# R7FA4L1BD register map
Vendor: Renesas Electronics Corporation; Series: RA4; File version: 0.90.02
CPU: CM33 r0p4, little endian, MPU, FPU, VTOR, 4 interrupt priority bits, 96 interrupts
Registers are 32-bit, read-write, reset 0x0 unless marked. A register's access mark holds for its fields unless they carry their own. Offsets are from the block's base; [hi:lo] are bit positions; {n}, {i} and the like mark numbered series; <NAME> marks a mode.

## SYSC — System Control
Base 0x4001E000
0x0C SBYCR 16-bit — Standby Control Register
  [15] SSBY — Software Standby Mode Select
    0=Sleep mode; 1=Software Standby mode
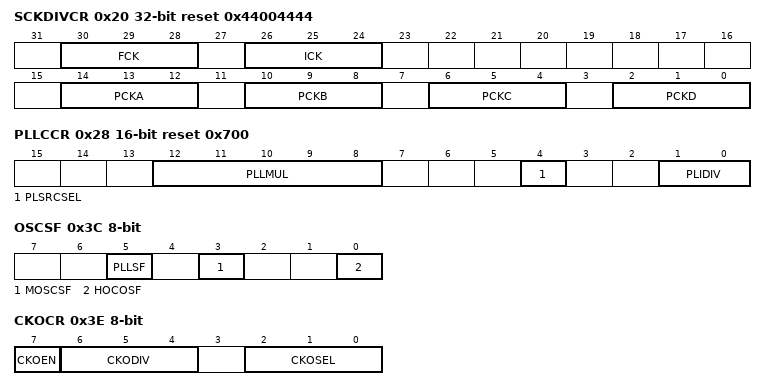
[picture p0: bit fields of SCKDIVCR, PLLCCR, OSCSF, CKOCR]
0x20 SCKDIVCR reset 0x44004444 — System Clock Division Control Register
  [all] fields
    0=x 1/1; 1=x 1/2; 2=x 1/4; 3=x 1/8; 4=x 1/16; 5=x 1/32; 6=x 1/64; other=Others (Setting prohibited.)
  [30:28] FCK — FlashIF Clock (FCLK) Select
  [26:24] ICK — System Clock (ICLK) Select
  [14:12] PCKA — Peripheral Module Clock A (PCLKA) Select
  [10:8] PCKB — Peripheral Module Clock B (PCLKB) Select
  [6:4] PCKC — Peripheral Module Clock C (PCLKC) Select
  [2:0] PCKD — Peripheral Module Clock D (PCLKD) Select
0x26 SCKSCR 8-bit reset 0x1 — System Clock Source Control Register
  [2:0] CKSEL — Clock Source Select
    0=HOCO; 1=MOCO; 2=LOCO; 3=Main clock oscillator (MOSC); 4=Sub-clock oscillator (SOSC); 5=PLL; 6=Setting prohibited; 7=Setting prohibited
0x28 PLLCCR 16-bit reset 0x700 — PLL Clock Control Register
  [12:8] PLLMUL range 0x13..0x3B — PLL Frequency Multiplication Factor Select
  [4] PLSRCSEL — PLL Clock Source Select
    0=Main clock oscillator; 1=HOCO
  [1:0] PLIDIV — PLL Input Frequency Division Ratio Select
    0=/1; 1=/4; 2=/6; other=Others (Setting prohibited)
0x2A PLLCR 8-bit reset 0x1 — PLL Control Register
  [0] PLLSTP — PLL Stop Control
    0=PLL is operating; 1=PLL is stopped
0x31 MEMWAIT 8-bit — Memory Wait Cycle Control Register for Code Flash
  [1:0] MEMWAIT — Memory Wait Cycle Select for Code Flash
    0=No wait; 1=One wait; 2=Two waits; other=Others (Setting prohibited)
0x32 MOSCCR 8-bit reset 0x1 — Main Clock Oscillator Control Register
  [0] MOSTP — Main Clock Oscillator Stop
    0=Operate the main clock oscillator; 1=Stop the main clock oscillator
0x36 HOCOCR 8-bit (reset mask 0xFE) — High-Speed On-Chip Oscillator Control Register
  [0] HCSTP — HOCO Stop
    0=Operate the HOCO clock; 1=Stop the HOCO clock
0x38 MOCOCR 8-bit — Middle-Speed On-Chip Oscillator Control Register
  [0] MCSTP — MOCO Stop
    0=MOCO clock is operating; 1=MOCO clock is stopped
0x3C OSCSF 8-bit ro (reset mask 0xFE) — Oscillation Stabilization Flag Register
  [5] PLLSF — PLL Clock Oscillation Stabilization Flag
    0=The PLL clock is stopped, or oscillation of the PLL clock is not stable yet; 1=The PLL clock is stable, so is available for use as the system clock
  [3] MOSCSF — Main Clock Oscillation Stabilization Flag
    0=The main clock oscillator is stopped (MOSTP = 1) or is not yet stable; 1=The main clock oscillator is stable, so is available for use as the system clock
  [0] HOCOSF — HOCO Clock Oscillation Stabilization Flag
    0=The HOCO clock is stopped or is not yet stable; 1=The HOCO clock is stable, so is available for use as the system clock
0x3E CKOCR 8-bit — Clock Out Control Register
  [7] CKOEN — Clock Out Enable
    0=Disable clock out; 1=Enable clock out
  [6:4] CKODIV — Clock Output Frequency Division Ratio
    0=x 1/1; 1=x 1/2; 2=x 1/4; 3=x 1/8; 4=x 1/16; 5=x 1/32; 6=x 1/64; 7=x 1/128
  [2:0] CKOSEL — Clock Out Source Select
    0=HOCO (value after reset); 1=MOCO; 2=LOCO; 3=MOSC; 4=SOSC; other=Others (Setting prohibited)
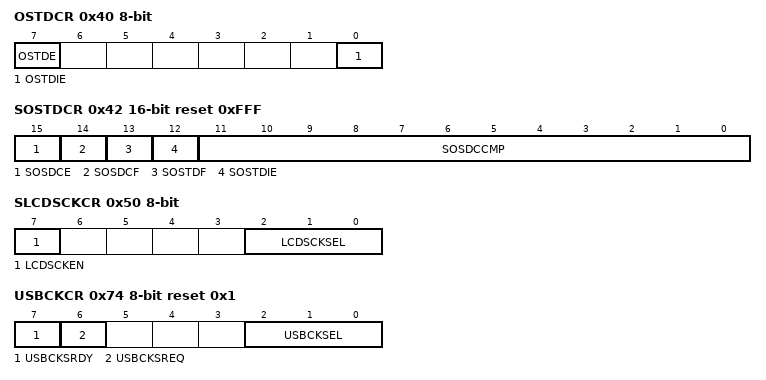
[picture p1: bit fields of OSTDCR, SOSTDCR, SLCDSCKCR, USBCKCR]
0x40 OSTDCR 8-bit — Oscillation Stop Detection Control Register
  [7] OSTDE — Oscillation Stop Detection Function Enable
    0=Disable oscillation stop detection function; 1=Enable oscillation stop detection function
  [0] OSTDIE — Oscillation Stop Detection Interrupt Enable
    0=Disable oscillation stop detection interrupt (do not notify the POEG); 1=Enable oscillation stop detection interrupt (notify the POEG)
0x41 OSTDSR 8-bit — Oscillation Stop Detection Status Register
  [0] OSTDF — Oscillation Stop Detection Flag
    0=Main clock oscillation stop not detected; 1=Main clock oscillation stop detected
0x42 SOSTDCR 16-bit reset 0xFFF — Sub-Clock Oscillation Stop Detection Control Register
  [15] SOSDCE — Control of Sub-Clock Oscillation Stop Detector Operation
    0=Stop operation of the sub-clock oscillation stop detector; 1=Start operation of the sub-clock oscillation stop detector
  [14] SOSDCF ro — Status of Sub-Clock Oscillation Stop Detector Operation
    0=Stop operation of the sub-clock oscillation stop detector; 1=Run operation of the sub-clock oscillation stop detector
  [13] SOSTDF ro — Sub-Clock Oscillation Stop Detection Flag
    0=Sub-clock oscillation stop not detected; 1=Sub-clock oscillation stop detected
  [12] SOSTDIE — Sub-Clock Oscillation Stop Detection Interrupt Enable
    0=Disable sub-clock oscillation stop detection interrupt; 1=Enable sub-clock oscillation stop detection interrupt
  [11:0] SOSDCCMP — Sub-Clock Oscillation Stop Detection Time
0x50 SLCDSCKCR 8-bit — Segment LCD Source Clock Control Register
  [7] LCDSCKEN — Segment LCD Source Clock (LCDSRCCLK) Out Enable
    0=Segment LCD source clock out is disabled; 1=Segment LCD source clock out is enabled
  [2:0] LCDSCKSEL — Segment LCD Source Clock (LCDSRCCLK) Select
    0=LOCO; 1=SOSC; 2=MOSC; 4=HOCO; other=Others (Setting prohibited)
0x61 MOCOUTCR 8-bit — MOCO User Trimming Control Register
  [7:0] MOCOUTRM — MOCO User Trimming
0x62 HOCOUTCR 8-bit — HOCO User Trimming Control Register
  [7:0] HOCOUTRM — HOCO User Trimming
0x6E CANFDCKDIVCR 8-bit — CANFD Clock Division Control Register
  [2:0] CANFDCKDIV — CANFD clock (CANFDCLK) Division Select
    0=/1 (value after reset); 1=/2; 2=/4; 3=/6; 4=/8; other=Others (Setting prohibited)
0x71 I3CCKDIVCR 8-bit — I3C Clock Division Control Register
  [2:0] I3CCKDIV — I3C Clock (I3CCLK) Division Select
    0=/1 (value after reset); 1=/2; 2=/4; 3=/6; 4=/8; 5=/3; 6=/5; other=Others (Setting prohibited)
0x74 USBCKCR 8-bit reset 0x1 — USB Clock Control Register
  [7] USBCKSRDY ro — USB Clock (USBCLK) Switching Ready state flag
    0=Impossible to Switch; 1=Possible to Switch
  [6] USBCKSREQ — USB Clock (USBCLK) Switching Request
    0=No request; 1=Request switching
  [2:0] USBCKSEL — USB Clock (USBCLK) Source Select
    5=PLL; other=Others (Setting prohibited.)
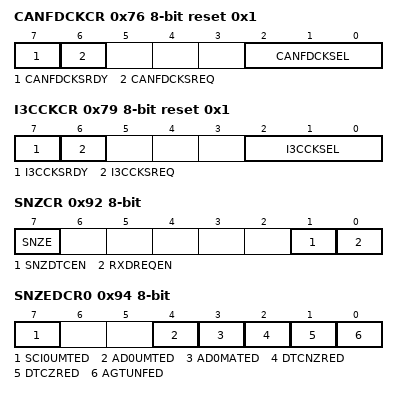
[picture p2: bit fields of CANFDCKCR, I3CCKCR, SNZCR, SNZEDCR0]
0x76 CANFDCKCR 8-bit reset 0x1 — CANFD Clock Control Register
  [7] CANFDCKSRDY ro — CANFD clock (CANFDCLK) Switching Ready State Flag
    0=Switching not possible; 1=Switching possible
  [6] CANFDCKSREQ — CANFD clock (CANFDCLK) Switching Request
    0=No request; 1=Request switching
  [2:0] CANFDCKSEL — CANFD clock (CANFDCLK) Source Select
    0=HOCO; 1=MOCO (value after reset); 2=LOCO; 3=Main clock oscillator; 4=Sub-clock oscillator; 5=PLL; other=Others (Setting prohibited)
0x79 I3CCKCR 8-bit reset 0x1 — I3C Clock Control Register
  [7] I3CCKSRDY ro — I3C clock (I3CCLK) Switching Ready State Flag
    0=Impossible to switch; 1=Possible to switch
  [6] I3CCKSREQ — I3C clock (I3CCLK) Switching Request
    0=No request; 1=Request switching
  [2:0] I3CCKSEL — I3C clock (I3CCLK) Source Select
    0=HOCO; 1=MOCO (value after reset); 2=LOCO; 3=Main clock oscillator; 4=Sub-clock oscillator; 5=PLL
0x92 SNZCR 8-bit — Snooze Control Register
  [7] SNZE — Snooze mode Enable
    0=Disable Snooze mode; 1=Enable Snooze mode
  [1] SNZDTCEN — DTC Enable in Snooze mode
    0=Disable DTC operation; 1=Enable DTC operation
  [0] RXDREQEN — RXD0 Snooze Request Enable
    0=Ignore RXD0 falling edge in Software Standby mode; 1=Detect RXD0 falling edge in Software Standby mode
0x94 SNZEDCR0 8-bit — Snooze End Control Register 0
  [all] fields
    0=Disable the snooze end request; 1=Enable the snooze end request
  [7] SCI0UMTED — SCI0 Address Mismatch Snooze End Enable
  [4] AD0UMTED — ADC12 Compare Mismatch Snooze End Enable
  [3] AD0MATED — ADC12 Compare Match Snooze End Enable
  [2] DTCNZRED — Not Last DTC Transmission Completion Snooze End Enable
  [1] DTCZRED — Last DTC Transmission Completion Snooze End Enable
  [0] AGTUNFED — AGT1 Underflow Snooze End Enable
0x95 SNZEDCR1 8-bit — Snooze End Control Register 1
  [1] CTSUNAJED — CTSU non-touch automatic judgment Snooze End Enable
    0=Disable the Snooze End request; 1=Enable the Snooze End request
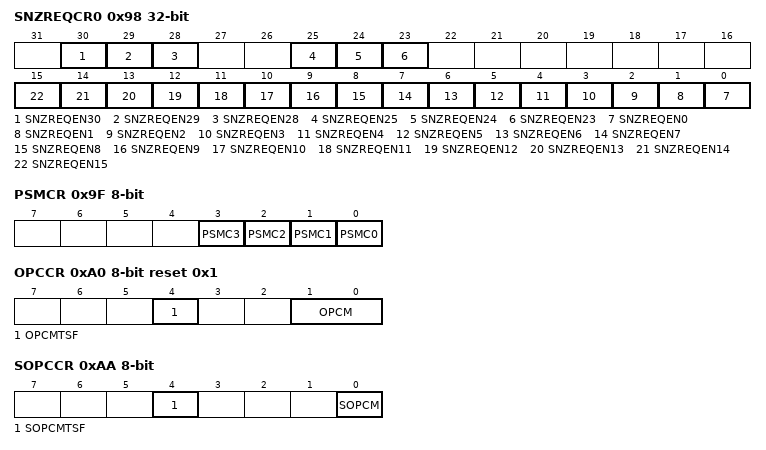
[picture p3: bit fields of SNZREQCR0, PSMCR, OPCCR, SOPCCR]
0x98 SNZREQCR0 — Snooze Request Control Register 0
  [all] fields
    0=Disable the snooze request; 1=Enable the snooze request
  [30] SNZREQEN30 — Enable AGT1 compare match B snooze request
  [29] SNZREQEN29 — Enable AGT1 compare match A snooze request
  [28] SNZREQEN28 — Enable AGT1 underflow snooze request
  [25] SNZREQEN25 — Enable RTC period snooze request
  [24] SNZREQEN24 — Enable RTC alarm snooze request
  [23] SNZREQEN23 — Enable ACMP_LP0 snooze request
  [n] SNZREQEN{n} (n=0..15) — Enable IRQ{n} pin snooze request
0x9F PSMCR 8-bit — Power Save Memory Control Register
  [3] PSMC3 — Power Save Memory Control bit 3
    0=The SRAM data of 0x2000_C000 to 0x2000_FFFF area is retained in Software Standby mode; 1=The SRAM data of 0x2000_C000 to 0x2000_FFFF area is not retained in Software Standby mode
  [2] PSMC2 — Power Save Memory Control bit 2
    0=The SRAM data of 0x2000_8000 to 0x2000_BFFF area is retained in Software Standby mode; 1=The SRAM data of 0x2000_8000 to 0x2000_BFFF area is not retained in Software Standby mode
  [1] PSMC1 — Power Save Memory Control bit 1
    0=The SRAM data of 0x2000_4000 to 0x2000_7FFF area is retained in Software Standby mode; 1=The SRAM data of 0x2000_4000 to 0x2000_7FFF area is not retained in Software Standby mode
  [0] PSMC0 — Power Save Memory Control bit 0
    0=The SRAM data of 0x2000_0000 to 0x2000_3FFF area is retained in Software Standby mode; 1=The SRAM data of 0x2000_0000 to 0x2000_3FFF area is not retained in Software Standby mode
0xA0 OPCCR 8-bit reset 0x1 — Operating Power Control Register
  [4] OPCMTSF ro — Operating Power Control Mode Transition Status Flag
    0=Transition completed; 1=During transition
  [1:0] OPCM — Operating Power Control Mode Select
    0=High-speed mode; 1=Middle-speed mode; 2=Setting prohibited; 3=Low-speed mode
0xA2 MOSCWTCR 8-bit reset 0x5 — Main Clock Oscillator Wait Control Register
  [3:0] MSTS — Main Clock Oscillator Wait Time Setting
    0=Wait time = 2 cycles (0.25 us); 1=Wait time = 1024 cycles (128 us); 2=Wait time = 2048 cycles (256 us); 3=Wait time = 4096 cycles (512 us); 4=Wait time = 8192 cycles (1024 us); 5=Wait time = 16384 cycles (2048 us); 6=Wait time = 32768 cycles (4096 us); 7=Wait time = 65536 cycles (8192 us); 8=Wait time = 131072 cycles (16384 us); 9=Wait time = 262144 cycles (32768 us); other=Others (Setting prohibited)
0xAA SOPCCR 8-bit — Sub Operating Power Control Register
  [4] SOPCMTSF ro — Operating Power Control Mode Transition Status Flag
    0=Transition completed; 1=During transition
  [0] SOPCM — Sub Operating Power Control Mode Select
    0=Other than Subosc-speed mode; 1=Subosc-speed mode
0xAC LDOCR 8-bit — LDO Control Register
  [0] CHG0 — Charge up 0
    0=LDO normal operating mode; 1=LDO high performance mode
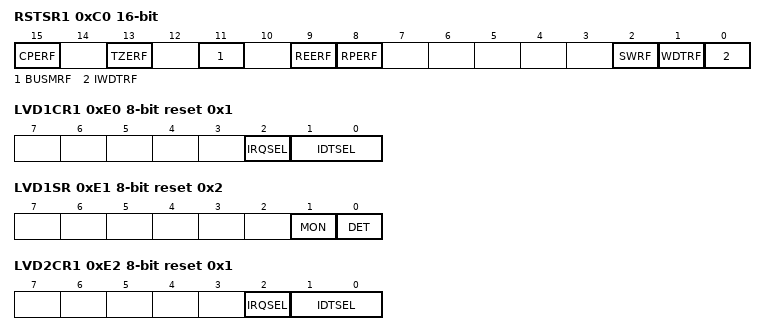
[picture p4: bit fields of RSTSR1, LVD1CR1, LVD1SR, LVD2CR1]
0xC0 RSTSR1 16-bit (reset mask 0x54F8) — Reset Status Register 1
  [15] CPERF — Cache Parity Error Reset Detect Flag
    0=Cache Parity error reset not detected; 1=Cache Parity error reset detected
  [13] TZERF — TrustZone Error Reset Detect Flag
    0=TrustZone error reset not detected; 1=TrustZone error reset detected
  [11] BUSMRF — Bus Master MPU Error Reset Detect Flag
    0=Bus master MPU error reset not detected; 1=Bus master MPU error reset detected
  [9] REERF — SRAM ECC Error Reset Detect Flag
    0=SRAM ECC error reset not detected; 1=SRAM ECC error reset detected
  [8] RPERF — SRAM Parity Error Reset Detect Flag
    0=SRAM parity error reset not detected; 1=SRAM parity error reset detected
  [2] SWRF — Software Reset Detect Flag
    0=Software reset not detected; 1=Software reset detected
  [1] WDTRF — Watchdog Timer Reset Detect Flag
    0=Watchdog timer reset not detected; 1=Watchdog timer reset detected
  [0] IWDTRF — Independent Watchdog Timer Reset Detect Flag
    0=Independent watchdog timer reset not detected; 1=Independent watchdog timer reset detected
0xE0 LVD1CR1 8-bit reset 0x1 — Voltage Monitor 1 Circuit Control Register
  [2] IRQSEL — Voltage Monitor 1 Interrupt Type Select
    0=Non-maskable interrupt; 1=Maskable interrupt
  [1:0] IDTSEL — Voltage Monitor 1 Interrupt Generation Condition Select
    0=When VCC >= Vdet1 (rise) is detected; 1=When VCC < Vdet1 (fall) is detected; 2=When fall and rise are detected; 3=Settings prohibited
0xE1 LVD1SR 8-bit reset 0x2 — Voltage Monitor 1 Circuit Status Register
  [1] MON ro — Voltage Monitor 1 Signal Monitor Flag
    0=VCC < Vdet1; 1=VCC >= Vdet1 or MON is disabled
  [0] DET — Voltage Monitor 1 Voltage Variation Detection Flag
    0=Not detected; 1=Vdet1 crossing is detected
0xE2 LVD2CR1 8-bit reset 0x1 — Voltage Monitor 2 Circuit Control Register 1
  [2] IRQSEL — Voltage Monitor 2 Interrupt Type Select
    0=Non-maskable interrupt; 1=Maskable interrupt
  [1:0] IDTSEL — Voltage Monitor 2 Interrupt Generation Condition Select
    0=When VCC or the EXLVD pin >= Vdet2 (rise) is detected; 1=When VCC or the EXLVD pin < Vdet2 (fall) is detected; 2=When fall and rise are detected; 3=Settings prohibited
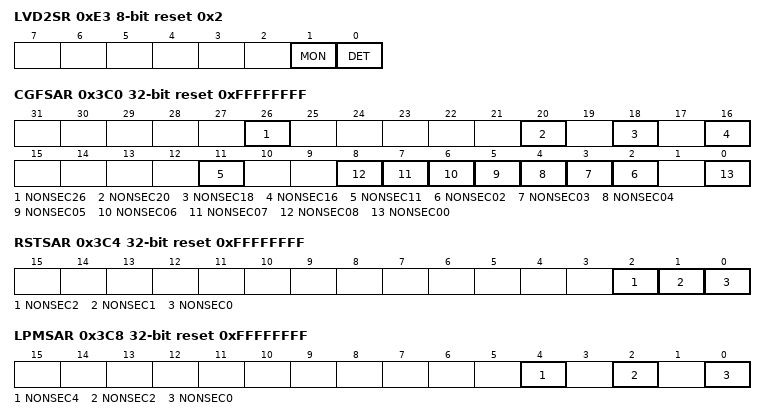
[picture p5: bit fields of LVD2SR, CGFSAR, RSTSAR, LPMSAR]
0xE3 LVD2SR 8-bit reset 0x2 — Voltage Monitor 2 Circuit Status Register
  [1] MON ro — Voltage Monitor 2 Signal Monitor Flag
    0=VCC or the EXLVD pin < Vdet2; 1=VCC or the EXLVD pin >= Vdet2 or MON is disabled
  [0] DET — Voltage Monitor 2 Voltage Variation Detection Flag
    0=Not detected; 1=Vdet2 crossing is detected
0x3C0 CGFSAR reset 0xFFFFFFFF — Clock Generation Function Security Attribute Register
  [all] fields
    0=Secure; 1=Non Secure
  [26] NONSEC26 — Non Secure Attribute bit 26
  [20] NONSEC20 — Non Secure Attribute bit 20
  [18] NONSEC18 — Non Secure Attribute bit 18
  [16] NONSEC16 — Non Secure Attribute bit 16
  [11] NONSEC11 — Non Secure Attribute bit 11
  [n] NONSEC{n:02} (n=2..8) — Non Secure Attribute bit {n:02}
  [0] NONSEC00 — Non Secure Attribute bit 00
0x3C4 RSTSAR reset 0xFFFFFFFF — Reset Security Attribution Register
  [all] fields
    0=Secure; 1=Non Secure
  [2] NONSEC2 — Non Secure Attribute bit 2
  [1] NONSEC1 — Non Secure Attribute bit 1
  [0] NONSEC0 — Non Secure Attribute bit 0
0x3C8 LPMSAR reset 0xFFFFFFFF — Low Power Mode Security Attribution Register
  [all] fields
    0=Secure; 1=Non Secure
  [4] NONSEC4 — Non Secure Attribute bit 4
  [2] NONSEC2 — Non Secure Attribute bit 2
  [0] NONSEC0 — Non Secure Attribute bit 0
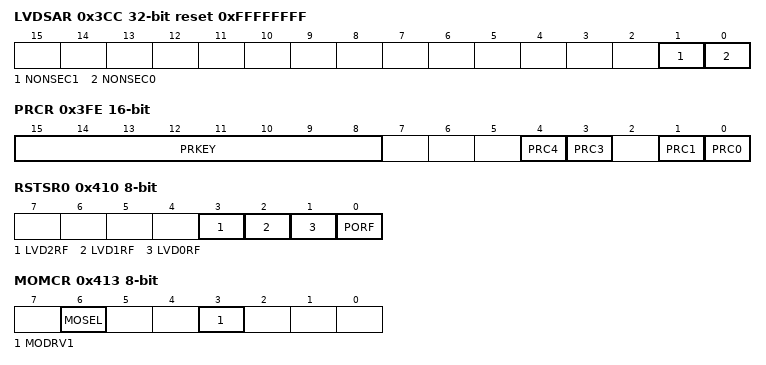
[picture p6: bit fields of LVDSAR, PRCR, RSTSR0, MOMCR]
0x3CC LVDSAR reset 0xFFFFFFFF — Low Voltage Detection Security Attribution Register
  [1] NONSEC1 — Non Secure Attribute bit 1
    0=Secure; 1=Non Secure
  [0] NONSEC0 — Non Secure Attribute bit 0
    0=Secure; 1=Non Secure
0x3FE PRCR 16-bit — Protect Register
  [15:8] PRKEY wo — PRC Key Code
  [4] PRC4
    0=Disable writes; 1=Enable writes
  [3] PRC3 — Enable writing to the registers related to the LVD
    0=Disable writes; 1=Enable writes
  [1] PRC1 — Enable writing to the registers related to the low power modes
    0=Disable writes; 1=Enable writes
  [0] PRC0 — Enable writing to the registers related to the clock generation circuit
    0=Disable writes; 1=Enable writes
0x40E SYOCDCR 8-bit — System Control OCD Control Register
  [7] DBGEN — Debugger Enable bit
    0=On-chip debugger is disabled; 1=On-chip debugger is enabled
0x410 RSTSR0 8-bit (reset mask 0xF0) — Reset Status Register 0
  [3] LVD2RF — Voltage Monitor 2 Reset Detect Flag
    0=Voltage monitor 2 reset not detected; 1=Voltage monitor 2 reset detected
  [2] LVD1RF — Voltage Monitor 1 Reset Detect Flag
    0=Voltage monitor 1 reset not detected; 1=Voltage monitor 1 reset detected
  [1] LVD0RF — Voltage Monitor 0 Reset Detect Flag
    0=Voltage monitor 0 reset not detected; 1=Voltage monitor 0 reset detected
  [0] PORF — Power-On Reset Detect Flag
    0=Power-on reset not detected; 1=Power-on reset detected
0x411 RSTSR2 8-bit (reset mask 0xFE) — Reset Status Register 2
  [0] CWSF — Cold/Warm Start Determination Flag
    0=Cold start; 1=Warm start
0x413 MOMCR 8-bit — Main Clock Oscillator Mode Oscillation Control Register
  [6] MOSEL — Main Clock Oscillator Switching
    0=Resonator; 1=External clock input
  [3] MODRV1 — Main Clock Oscillator Drive Capability 1 Switching
    0=10 MHz to 20 MHz; 1=1 MHz to 10 MHz
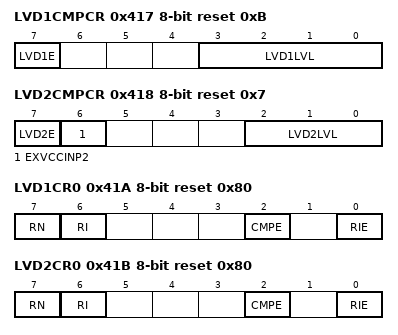
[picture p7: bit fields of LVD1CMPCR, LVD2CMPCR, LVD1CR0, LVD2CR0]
0x417 LVD1CMPCR 8-bit reset 0xB — Voltage Monitoring 1 Comparator Control Register
  [7] LVD1E — Voltage Detection 1 Enable
    0=Voltage detection 1 circuit disabled; 1=Voltage detection 1 circuit enabled
  [3:0] LVD1LVL — Voltage Detection 1 Level Select
    {v}=Vdet1_{v} (v=0..9); 10=Vdet1_A; 11=Vdet1_B; other=Others (Setting prohibited)
0x418 LVD2CMPCR 8-bit reset 0x7 — Voltage Monitoring 2 Comparator Control Register
  [7] LVD2E — Voltage Detection 2 Enable
    0=Voltage detection 2 circuit disabled; 1=Voltage detection 2 circuit enabled
  [6] EXVCCINP2 — Voltage Detection 2 Comparison (Voltage external input select)
    0=Power supply voltage (VCC); 1=EXLVD pin input voltage
  [2:0] LVD2LVL — Voltage Detection 2 Level Select
    {v}=Vdet2_{v} (v=0..7)
0x41A LVD1CR0 8-bit reset 0x80 — Voltage Monitor 1 Circuit Control Register 0
  [7] RN — Voltage Monitor 1 Reset Negate Select
    0=Negate after a stabilization time (tLVD1) when VCC > Vdet1 is detected; 1=Negate after a stabilization time (tLVD1) on assertion of the LVD1 reset
  [6] RI — Voltage Monitor 1 Circuit Mode Select
    0=Generate voltage monitor 1 interrupt on Vdet1 crossing; 1=Enable voltage monitor 1 reset when the voltage falls to and below Vdet1
  [2] CMPE — Voltage Monitor 1 Circuit Comparison Result Output Enable
    0=Disable voltage monitor 1 circuit comparison result output; 1=Enable voltage monitor 1 circuit comparison result output
  [0] RIE — Voltage Monitor 1 Interrupt/Reset Enable
    0=Disable; 1=Enable
0x41B LVD2CR0 8-bit reset 0x80 — Voltage Monitor 2 Circuit Control Register 0
  [7] RN — Voltage Monitor 2 Reset Negate Select
    0=Negate after a stabilization time (tLVD2) when VCC or the EXLVD pin > Vdet2 is detected; 1=Negate after a stabilization time (tLVD2) on assertion of the LVD2 reset
  [6] RI — Voltage Monitor 2 Circuit Mode Select
    0=Generate voltage monitor 2 interrupt on Vdet2 crossing; 1=Enable voltage monitor 2 reset when the voltage falls to and below Vdet2
  [2] CMPE — Voltage Monitor 2 Circuit Comparison Result Output Enable
    0=Disable voltage monitor 2 circuit comparison result output; 1=Enable voltage monitor 2 circuit comparison result output
  [0] RIE — Voltage Monitor 2 Interrupt/Reset Enable
    0=Disable; 1=Enable
0x480 SOSCCR 8-bit reset 0x1 — Sub-Clock Oscillator Control Register
  [0] SOSTP — Sub Clock Oscillator Stop
    0=Operate the sub-clock oscillator; 1=Stop the sub-clock oscillator
0x481 SOMCR 8-bit — Sub-Clock Oscillator Mode Control Register
  [1:0] SODRV — Sub-Clock Oscillator Drive Capability Switching
    0=Normal mode; 1=Low power mode 1; 2=Low power mode 2; 3=Low power mode 3
0x482 SOMRG 8-bit — Sub-Clock Oscillator Margin Check Register
  [1:0] SOSCMRG — Sub Clock Oscillator Margin check Switching
    0=Normal current; 1=Lower margin check; 2=Upper margin check; 3=Setting prohibited
0x490 LOCOCR 8-bit — Low-Speed On-Chip Oscillator Control Register
  [0] LCSTP — LOCO Stop
    0=Operate the LOCO clock; 1=Stop the LOCO clock
0x492 LOCOUTCR 8-bit — LOCO User Trimming Control Register
  [7:0] LOCOUTRM — LOCO User Trimming
